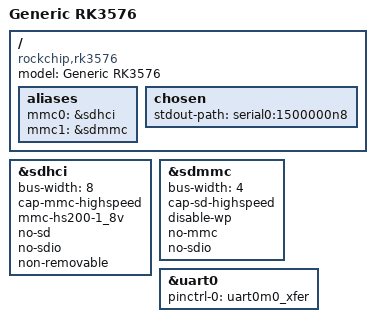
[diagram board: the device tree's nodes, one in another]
// SPDX-License-Identifier: (GPL-2.0+ OR MIT)
/*
 * Minimal generic DT for RK3576 with eMMC and SD-card enabled
 */

/dts-v1/;
#include "rk3576.dtsi"

/ {
	model = "Generic RK3576";
	compatible = "rockchip,rk3576";

	aliases {
		mmc0 = &sdhci;
		mmc1 = &sdmmc;
	};

	chosen {
		stdout-path = "serial0:1500000n8";
	};
};

&sdhci {
	bus-width = <8>;
	cap-mmc-highspeed;
	mmc-hs200-1_8v;
	no-sd;
	no-sdio;
	non-removable;
	status = "okay";
};

&sdmmc {
	bus-width = <4>;
	cap-sd-highspeed;
	disable-wp;
	no-mmc;
	no-sdio;
	status = "okay";
};

&uart0 {
	pinctrl-0 = <&uart0m0_xfer>;
	status = "okay";
};
